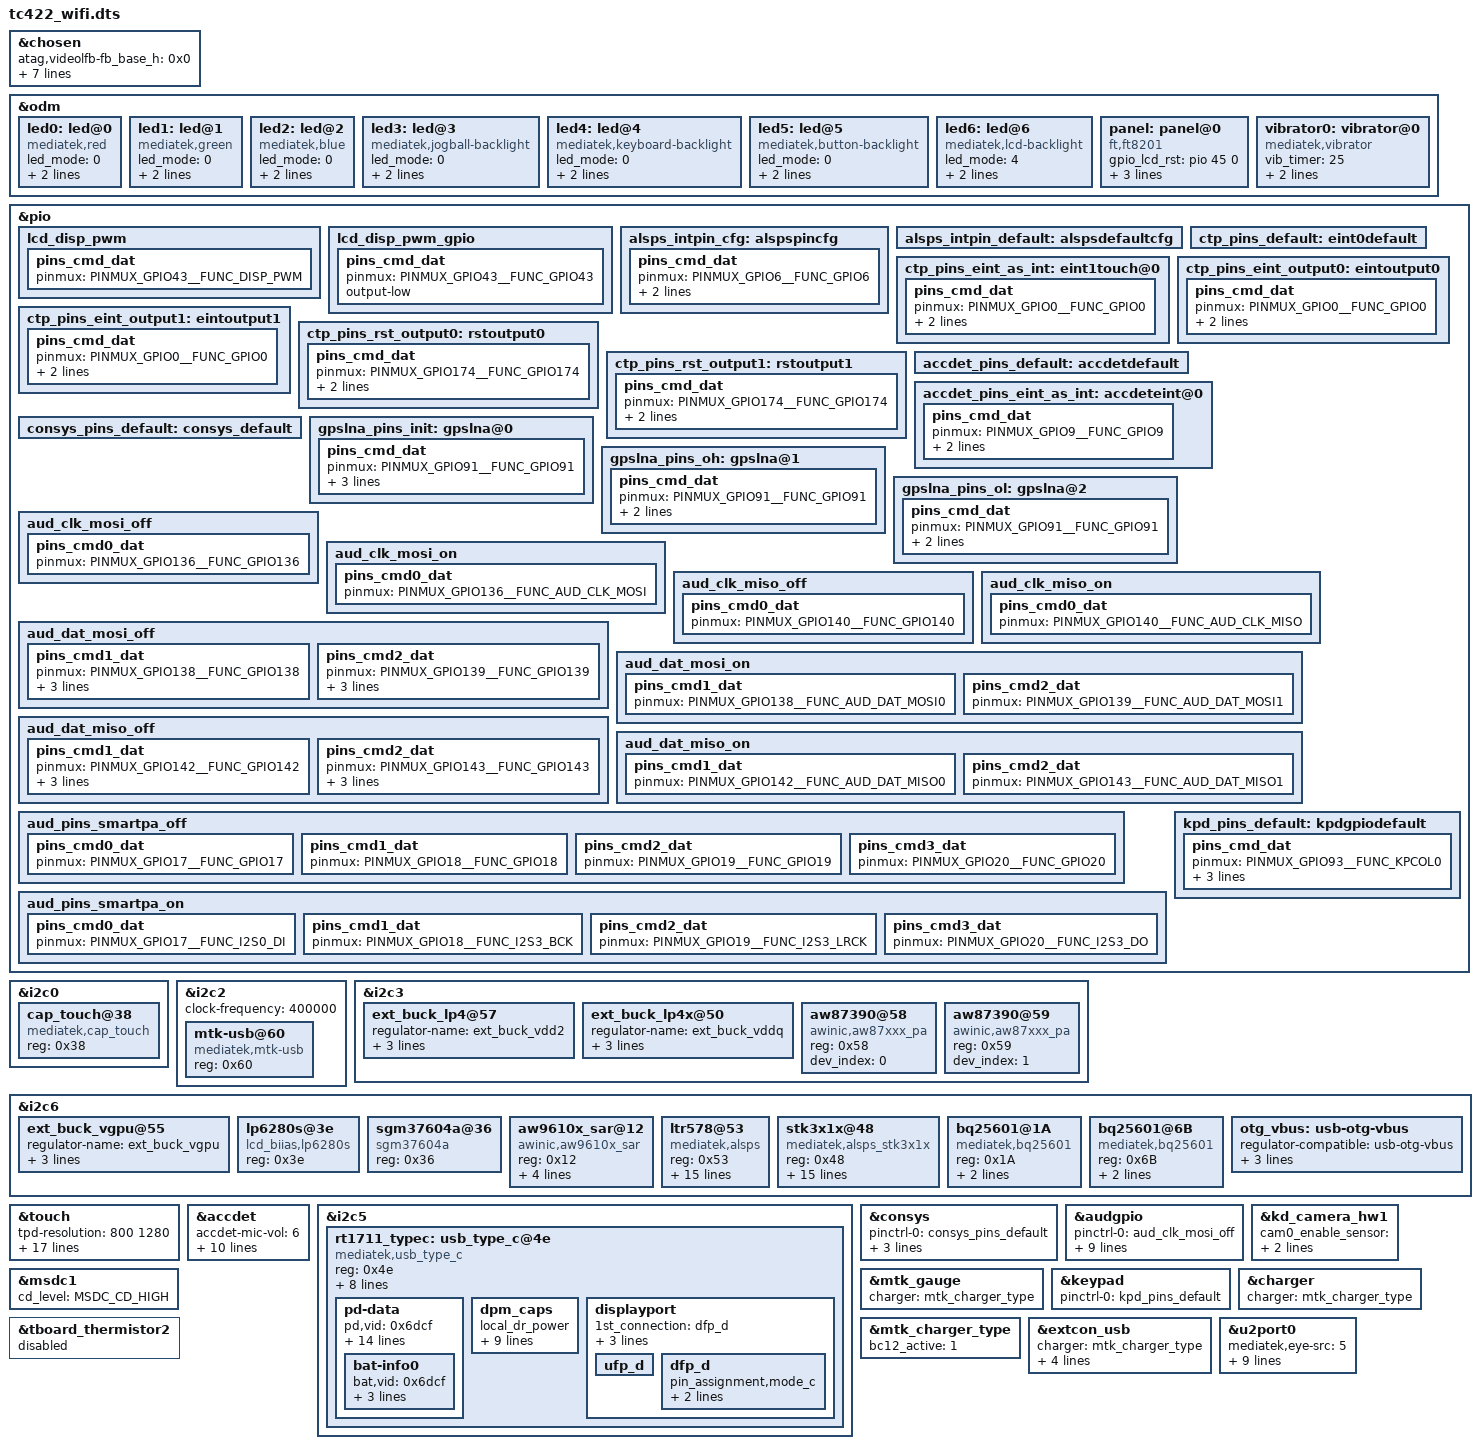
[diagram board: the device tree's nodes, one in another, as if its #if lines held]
// SPDX-License-Identifier: GPL-2.0+
/*
 * Copyright (c) 2019 MediaTek Inc.
 *
 */

#include <dt-bindings/interrupt-controller/arm-gic.h>
#include <dt-bindings/interrupt-controller/irq.h>
#include <dt-bindings/pinctrl/mt6761-pinfunc.h>
#include <dt-bindings/mmc/mt6761-msdc.h>
#include <dt-bindings/clock/mt6761-clk.h>

/dts-v1/;
/plugin/;

/* chosen */
&chosen {

	/* fpga may has no lk, we need to specify display info here */
	/* fb buffer is reserved using this dts by memory node above */
	atag,videolfb-fb_base_h = <0x0>;
	atag,videolfb-fb_base_l = <0x5e605000>;
	atag,videolfb-islcmfound = <1>;
	/* because no lk, so lcm is not inited */
	atag,videolfb-islcm_inited = <0>;
	atag,videolfb-fps= <6000>;
	atag,videolfb-vramSize= <0x017bb000>;
	atag,videolfb-lcmname= "nt35521_hd_dsi_vdo_truly_rt5081_drv";
};

&odm {
	led0:led@0 {
		compatible = "mediatek,red";
		led_mode = <0>;
		data = <1>;
		pwm_config = <0 0 0 0 0>;
	};
	led1:led@1 {
		compatible = "mediatek,green";
		led_mode = <0>;
		data = <1>;
		pwm_config = <0 0 0 0 0>;
	};
	led2:led@2 {
		compatible = "mediatek,blue";
		led_mode = <0>;
		data = <1>;
		pwm_config = <0 0 0 0 0>;
	};
	led3:led@3 {
		compatible = "mediatek,jogball-backlight";
		led_mode = <0>;
		data = <1>;
		pwm_config = <0 0 0 0 0>;
	};
	led4:led@4 {
		compatible = "mediatek,keyboard-backlight";
		led_mode = <0>;
		data = <1>;
		pwm_config = <0 0 0 0 0>;
	};
	led5:led@5 {
		compatible = "mediatek,button-backlight";
		led_mode = <0>;
		data = <1>;
		pwm_config = <0 0 0 0 0>;
	};
	led6:led@6 {
		compatible = "mediatek,lcd-backlight";
		led_mode = <4>;
		data = <1>;
		pwm_config = <0 3 0 0 0>;
	};
	panel: panel@0 {
		compatible = "ft,ft8201";
		gpio_lcd_rst = <&pio 45 0>;
		gpio_lcd_led_en = <&pio 153 0>;  //??????
		gpio_lcd_pwr_enp = <&pio 168 0>;//avdd
		gpio_lcd_pwr_enn = <&pio 173 0>;//avee
//		pinctrl-names = "disp_pwm", "disp_pwm_gpio";
//		pinctrl-0 = <&lcd_disp_pwm>;
//		pinctrl-1 = <&lcd_disp_pwm_gpio>;
	};
	vibrator0:vibrator@0 {
		compatible = "mediatek,vibrator";
		vib_timer = <25>;
		vib_limit = <9>;
		vib_vol= <9>;
	};
};

&pio {
	lcd_disp_pwm: lcd_disp_pwm {
		pins_cmd_dat {
			pinmux = <PINMUX_GPIO43__FUNC_DISP_PWM>;
		};
	};

	lcd_disp_pwm_gpio: lcd_disp_pwm_gpio {
		pins_cmd_dat {
			pinmux = <PINMUX_GPIO43__FUNC_GPIO43>;
			output-low;
		};
	};
};

&i2c0 {
	cap_touch@38 {
		compatible = "mediatek,cap_touch" ;
		reg = < 0x38 > ;
		status = "okay" ;
	};
};

&i2c2 {
	#address-cells = <1>;
	#size-cells = <0>;
	clock-frequency = <400000>;

	mtk-usb@60 {
		compatible = "mediatek,mtk-usb";
		reg = <0x60>;
		status = "okay";
	};
};

&i2c3 {
	ext_buck_lp4@57 {
		regulator-name ="ext_buck_vdd2";
		regulator-min-microvolt = <300000>;
		regulator-max-microvolt = <1300000>;
		vsel_pin = <0>;
	};

	ext_buck_lp4x@50 {
		regulator-name ="ext_buck_vddq";
		regulator-min-microvolt = <300000>;
		regulator-max-microvolt = <1300000>;
		vsel_pin = <1>;
	};

	aw87390@58 {
		compatible = "awinic,aw87xxx_pa";
		reg = <0x58>;
		//reset-gpio = <&pio 174 0>;
		dev_index = < 0 >;
		status = "okay";
	};

	aw87390@59 {
		compatible = "awinic,aw87xxx_pa";
		reg = <0x59>;
		//reset-gpio = <&pio 174 0>;
		dev_index = < 1 >;
		status = "okay";
	};

};

&i2c6 {
	ext_buck_vgpu@55 {
		regulator-name ="ext_buck_vgpu";
		regulator-min-microvolt = <300000>;
		regulator-max-microvolt = <1300000>;
		vsel_pin = <2>;
	};

	lp6280s@3e {
		compatible = "lcd_biias,lp6280s";
		reg = <0x3e>;
		status = "okay";
	};
	
	sgm37604a@36 {
		compatible = "sgm37604a";
		reg = <0x36>;
		status = "okay";
	};

	/*boe by linliangsong,add sensor,20220607,beigin*/
       aw9610x_sar@12 {
               compatible = "awinic,aw9610x_sar";
               reg = <0x12>;
               irq-gpio = <&pio 9 0x00>;
               aw9610x,using-firmware;
               //vcc0-supply = <&pm660l_l4>;
               channel_use_flag = <0x1f>;
               sar-num = < 0 >;
               status = "okay";
       };
      ltr578@53 {
               compatible = "mediatek,alsps";
               reg = <0x53>;
	       interrupt-parent = <&pio>;
	       interrupts = <6 IRQ_TYPE_LEVEL_LOW 6 0>;
	       debounce = <10 0>;
	       pinctrl-names = "pin_default", "pin_cfg";
	       pinctrl-0 = <&alsps_intpin_default>;
		pinctrl-1 = <&alsps_intpin_cfg>;
               status = "okay";
               i2c_num = <6>;
               i2c_addr = <0x53 0x0 0x0 0x00>;
               polling_mode_ps = <0>;
               polling_mode_als = <1>;
               power_id = <0xffff>;
               power_vol = <0>;
		als_level = <0 328 861 1377 3125 7721 7767 12621 23062 28430 33274 47116 57694 57694 65535>;
		als_value = <0 200 320 502 1004 2005 3058 5005 8008 10010 12000 16000 20000 20000 20000 20000>;
               //irq-gpio = <&pio 6 0x00>;               
      };
      /*boe by linliangsong,add sensor,20220607,end*/
      stk3x1x@48 {
               compatible = "mediatek,alsps_stk3x1x";
               reg = <0x48>;
               interrupt-parent = <&pio>;
               interrupts = <6 IRQ_TYPE_LEVEL_LOW 6 0>;
               debounce = <10 0>;
               pinctrl-names = "pin_default", "pin_cfg";
               pinctrl-0 = <&alsps_intpin_default>;
               pinctrl-1 = <&alsps_intpin_cfg>;
               status = "okay";
               i2c_num = <6>;
               i2c_addr = <0x48 0x0 0x0 0x00>;
               polling_mode_ps = <0>;
               polling_mode_als = <1>;
               power_id = <0xffff>;
               power_vol = <0>;
               als_level = <0 328 861 1377 3125 7721 7767 12621 23062 28430 33274 47116 57694 57694 65535>;
               als_value = <0 200 320 502 1004 2005 3058 5005 8008 10010 12000 16000 20000 20000 20000 20000>;
               //irq-gpio = <&pio 6 0x00>;
      };
	bq25601@1A {
		status = "okay";
		compatible = "mediatek,bq25601";
		reg = <0x1A>;
		charger_name = "primary_chg";
		alias_name = "sgm41513";
	};

	bq25601@6B {
		status = "okay";
		compatible = "mediatek,bq25601";
		reg = <0x6B>;
		charger_name = "primary_chg";
		alias_name = "sy6974";
	};

	otg_vbus: usb-otg-vbus {
		regulator-compatible = "usb-otg-vbus";
		regulator-name = "usb-otg-vbus";
		regulator-min-microvolt = <5000000>;
		regulator-max-microvolt = <5000000>;
	};
};
/*boe by linliangsong,add sensor,20220607,beigin*/
&pio {
	alsps_intpin_cfg: alspspincfg {

		pins_cmd_dat {
			pinmux = <PINMUX_GPIO6__FUNC_GPIO6>;
			slew-rate = <0>;
			bias-pull-up = <MTK_PUPD_SET_R1R0_01>;
		};
	};

	alsps_intpin_default: alspsdefaultcfg {

	};

};
/*boe by linliangsong,add sensor,20220607,end*/

/* TOUCH start */
&touch {
	tpd-resolution = <800 1280>;
	use-tpd-button = <0>;
	tpd-key-num = <3>;
	tpd-key-local= <139 172 158 0>;
	tpd-key-dim-local = <90 883 100 40 230
				 883 100 40 370 883 100 40 0 0 0 0>;
	tpd-max-touch-num = <10>;
	tpd-filter-enable = <0>;
	tpd-filter-pixel-density = <106>;
	tpd-filter-custom-prameters = <0 0 0 0 0 0 0 0 0 0 0 0>;
	tpd-filter-custom-speed = <0 0 0>;
	pinctrl-names = "default", "state_eint_as_int", "state_eint_output0",
		"state_eint_output1", "state_rst_output0", "state_rst_output1";
	pinctrl-0 = <&ctp_pins_default>;
	pinctrl-1 = <&ctp_pins_eint_as_int>;
	pinctrl-2 = <&ctp_pins_eint_output0>;
	pinctrl-3 = <&ctp_pins_eint_output1>;
	pinctrl-4 = <&ctp_pins_rst_output0>;
	pinctrl-5 = <&ctp_pins_rst_output1>;
	status = "okay";
};
&pio {
	ctp_pins_default: eint0default {
	};
	ctp_pins_eint_as_int: eint1touch@0 {
		pins_cmd_dat {
			pinmux = <PINMUX_GPIO0__FUNC_GPIO0>;
			slew-rate = <0>;
			bias-disable;
		};
	};
	ctp_pins_eint_output0: eintoutput0 {
		pins_cmd_dat {
			pinmux = <PINMUX_GPIO0__FUNC_GPIO0>;
			slew-rate = <1>;
			output-low;
		};
	};
	ctp_pins_eint_output1: eintoutput1 {
		pins_cmd_dat {
			pinmux = <PINMUX_GPIO0__FUNC_GPIO0>;
			slew-rate = <1>;
			output-high;
		};
	};
	ctp_pins_rst_output0: rstoutput0 {
		pins_cmd_dat {
			pinmux = <PINMUX_GPIO174__FUNC_GPIO174>;
			slew-rate = <1>;
			output-low;
		};
	};
	ctp_pins_rst_output1: rstoutput1 {
		pins_cmd_dat {
			pinmux = <PINMUX_GPIO174__FUNC_GPIO174>;
			slew-rate = <1>;
			output-high;
		};
	};
};
/* TOUCH end */
&accdet {
	accdet-mic-vol = <6>;
	headset-mode-setting = <0x500 0x500 1 0x1f0 0x800 0x800 0x20 0x44>;
	accdet-plugout-debounce = <1>;
	accdet-mic-mode = <1>;
	headset-eint-level-pol = <8>;
	headset-three-key-threshold = <0 80 220 400>;
	headset-three-key-threshold-CDD = <0 121 192 600>;
	headset-four-key-threshold = <0 58 121 192 400>;
	pinctrl-names = "default", "state_eint_as_int";
	pinctrl-0 = <&accdet_pins_default>;
	pinctrl-1 = <&accdet_pins_eint_as_int>;
	status = "okay";
};
&pio {
	accdet_pins_default: accdetdefault {
	};
	accdet_pins_eint_as_int: accdeteint@0 {
		pins_cmd_dat {
			pinmux = <PINMUX_GPIO9__FUNC_GPIO9>;
			slew-rate = <0>;
			bias-disable;
		};
	};
};

&i2c5 {
    status = "okay";

    rt1711_typec: usb_type_c@4e {
        compatible = "mediatek,usb_type_c";
        reg = <0x4e>;

        rt-tcpc,name = "type_c_port0"; /* tcpc_device's name */
        rt-tcpc,role_def = <5>; /* 0: Unknown, 1: SNK, 2: SRC */
                    /* 3: DRP, 4: Try.SRC, 5: Try.SNK */
        rt-tcpc,rp_level = <0>; /* 0: Default, 1: 1.5, 2: 3.0 */
        rt-tcpc,vconn_supply  = <1>;  /* 0: Never, 1: Always, */
                          /* 2: EMarkOnly, 3: StartOnly */
#if (CONFIG_MTK_GAUGE_VERSION == 30)
        rt-tcpc,notifier_supply_num = <3>;
#else
        rt-tcpc,notifier_supply_num = <2>;
#endif
        rt1711pd,intr_gpio = <&pio 5 0x0>;
        rt1711pd,intr_gpio_num = <5>;

		charger = <&charger>;

        pd-data {
            pd,vid = <0x6dcf>;
            pd,pid = <0x1711>;
            pd,source-cap-ext = <0x17116dcf 0x00000000 0x00000000
                         0x00000000 0x00000000 0x02000000>;
            pd,mfrs = "RichtekTCPC";

            /*
             *  VSAFE5V = 0, MAX_POWER = 1, CUSTOM = 2,
             *  MAX_POWER_LV = 0x21, MAX_POWER_LVIC = 0x31
             *  MAX_POWER_HV = 0x41, MAX_POWER_HVIC = 0x51
             */
            pd,charging_policy= <0x31>;

            /*
             * Fixed 5V, 500 mA <0x00019032>
             * Fixed 5V, 1A <0x00019064>
             * Fixed 5V, 2A <0x000190c8>
             * Fixed 5V, 3A <0x0001912c>
             * Fixed 9V, 500 mA <0x0002d032>
             * Fixed 9V, 1A <0x0002d064>
             * Fixed 9V, 2A <0x0002d0c8>
             * Fixed 9V, 3A <0x0002d12c>
             * Variable 5-9V, 1A <0x8642d064>
             * Variable 5-9V, 2A <0x8642d0c8>
             * Variable 5-9V, 3A <0x8642d12c>
             * PPS 3V~5.9V, 3A <0xC0761E3C>
             */
            pd,source-pdo-size = <1>;
            pd,source-pdo-data = <0x00019032>;
            pd,sink-pdo-size = <1>;
            pd,sink-pdo-data = <0x000190c8>;

            /*
             * No DP, host + device
             *  pd,id-vdo-size = <6>;
             *  pd,id-vdo-data = <0xd1406dcf 0x0 0x17110000
                          0x41800000 0x0 0x21800000>;
             * With DP
             *  pd,id-vdo-size = <6>;
             *  pd,id-vdo-data = <0xd5406dcf 0x0 0x17110000
                          0x41800000 0x0 0x21800000>;
             */

            pd,id-vdo-size = <6>;
            pd,id-vdo-data = <0xd1406dcf 0x0 0x17110000
                      0x41800000 0x0 0x21800000>;

            bat,nr = <1>;
            pd,country_nr = <0>;

            bat-info0 {
                bat,vid = <0x6dcf>;
                bat,pid = <0x1711>;
                bat,mfrs = "bat1";
                bat,design_cap = <5000>;
            };

            //bat-info1 {
            //  bat,vid = <0x8abc>;
            //  bat,pid = <0x5234>;
            //  bat,mfrs = "bat2";
            //  bat,design_cap = <4000>;
            //};

            //country0 {
            //  pd,country_code = <0x5457>;
            //  pd,country_len = <2>; /* max len = 26 */
            //  pd,country_data = <0xff 0xff>;
            //};

            //country1 {
            //  pd,country_code = <0x5553>;
            //  pd,country_len = <3>; /* max len = 26 */
            //  pd,country_data = <0xf1 0xf2 0xf3>;
            //};
        };
        dpm_caps {
            local_dr_power;
            local_dr_data;
            //local_ext_power;
            local_usb_comm;
            //local_usb_suspend;
            //local_high_cap;
            //local_give_back;
            local_no_suspend;
            local_vconn_supply;

            //attemp_discover_cable_dfp;
            attemp_enter_dp_mode;
           attemp_discover_cable;
            attemp_discover_id;

            /* 0: disable, 1: prefer_snk, 2: prefer_src */
            pr_check = <0>;
            //pr_reject_as_source;
            //pr_reject_as_sink;
            //pr_check_gp_source;
            //pr_check_gp_sink;

            /* 0: disable, 1: prefer_ufp, 2: prefer_dfp */
            dr_check = <0>;
            //dr_reject_as_dfp;
            //dr_reject_as_ufp;
        };
        displayport {
            /* connection type = "both", "ufp_d", "dfp_d" */
            1st_connection = "dfp_d";
            2nd_connection = "dfp_d";
            signal,dp_v13;
            //signal,dp_gen2;
            //usbr20_not_used;
            typec,receptacle;
            ufp_d {
                //pin_assignment,mode_a;
                //pin_assignment,mode_b;
                //pin_assignment,mode_c;
                //pin_assignment,mode_d;
                //pin_assignment,mode_e;
            };
            dfp_d {
                //pin_assignment,mode_a;
                //pin_assignment,mode_b;
                pin_assignment,mode_c;
                pin_assignment,mode_d;
                pin_assignment,mode_e;
                //pin_assignment,mode_f;
            };
        };
    };

};

/* CONSYS GPIO standardization */
&pio {
	consys_pins_default: consys_default {
	};
	gpslna_pins_init: gpslna@0 {
		pins_cmd_dat {
			pinmux = <PINMUX_GPIO91__FUNC_GPIO91>;
			slew-rate = <0>;
			bias-disable;
			output-low;
		};
	};
	gpslna_pins_oh: gpslna@1 {
		pins_cmd_dat {
			pinmux = <PINMUX_GPIO91__FUNC_GPIO91>;
			slew-rate = <1>;
			output-high;
		};
	};
	gpslna_pins_ol: gpslna@2 {
		pins_cmd_dat {
			pinmux = <PINMUX_GPIO91__FUNC_GPIO91>;
			slew-rate = <1>;
			output-low;
		};
	};
};
&consys {
	pinctrl-names = "default", "gps_lna_state_init",
		"gps_lna_state_oh", "gps_lna_state_ol";
	pinctrl-0 = <&consys_pins_default>;
	pinctrl-1 = <&gpslna_pins_init>;
	pinctrl-2 = <&gpslna_pins_oh>;
	pinctrl-3 = <&gpslna_pins_ol>;
	status = "okay";
};
/* CONSYS end */

/* AUDIO GPIO standardization */
&audgpio {
	pinctrl-names = "aud_clk_mosi_off",
			"aud_clk_mosi_on",
			"aud_clk_miso_off",
			"aud_clk_miso_on",
			"aud_dat_mosi_off",
			"aud_dat_mosi_on",
			"aud_dat_miso_off",
			"aud_dat_miso_on",
			"aud_smartpa_off",
			"aud_smartpa_on";
	pinctrl-0 = <&aud_clk_mosi_off>;
	pinctrl-1 = <&aud_clk_mosi_on>;
	pinctrl-2 = <&aud_clk_miso_off>;
	pinctrl-3 = <&aud_clk_miso_on>;
	pinctrl-4 = <&aud_dat_mosi_off>;
	pinctrl-5 = <&aud_dat_mosi_on>;
	pinctrl-6 = <&aud_dat_miso_off>;
	pinctrl-7 = <&aud_dat_miso_on>;
	pinctrl-8 = <&aud_pins_smartpa_off>;
	pinctrl-9 = <&aud_pins_smartpa_on>;
	status = "okay";
};

&pio {
	aud_clk_mosi_off: aud_clk_mosi_off {
		pins_cmd0_dat {
			pinmux = <PINMUX_GPIO136__FUNC_GPIO136>;
		};
	};

	aud_clk_mosi_on: aud_clk_mosi_on {
		pins_cmd0_dat {
			pinmux = <PINMUX_GPIO136__FUNC_AUD_CLK_MOSI>;
		};
	};

	aud_clk_miso_off: aud_clk_miso_off {
		pins_cmd0_dat {
			pinmux = <PINMUX_GPIO140__FUNC_GPIO140>;
		};
	};

	aud_clk_miso_on: aud_clk_miso_on {
		pins_cmd0_dat {
			pinmux = <PINMUX_GPIO140__FUNC_AUD_CLK_MISO>;
		};
	};

	aud_dat_mosi_off: aud_dat_mosi_off {
		pins_cmd1_dat {
			pinmux = <PINMUX_GPIO138__FUNC_GPIO138>;
			input-enable;
			slew-rate = <0>;
			bias-disable;
		};
		pins_cmd2_dat {
			pinmux = <PINMUX_GPIO139__FUNC_GPIO139>;
			input-enable;
			slew-rate = <0>;
			bias-disable;
		};
	};

	aud_dat_mosi_on: aud_dat_mosi_on {
		pins_cmd1_dat {
			pinmux = <PINMUX_GPIO138__FUNC_AUD_DAT_MOSI0>;
		};
		pins_cmd2_dat {
			pinmux = <PINMUX_GPIO139__FUNC_AUD_DAT_MOSI1>;
		};
	};

	aud_dat_miso_off: aud_dat_miso_off {
		pins_cmd1_dat {
			pinmux = <PINMUX_GPIO142__FUNC_GPIO142>;
			input-enable;
			slew-rate = <0>;
			bias-disable;
		};
		pins_cmd2_dat {
			pinmux = <PINMUX_GPIO143__FUNC_GPIO143>;
			input-enable;
			slew-rate = <0>;
			bias-disable;
		};
	};

	aud_dat_miso_on: aud_dat_miso_on {
		pins_cmd1_dat {
			pinmux = <PINMUX_GPIO142__FUNC_AUD_DAT_MISO0>;
		};
		pins_cmd2_dat {
			pinmux = <PINMUX_GPIO143__FUNC_AUD_DAT_MISO1>;
		};
	};

	aud_pins_smartpa_off: aud_pins_smartpa_off {
		pins_cmd0_dat {
			pinmux = <PINMUX_GPIO17__FUNC_GPIO17>;
		};
		pins_cmd1_dat {
			pinmux = <PINMUX_GPIO18__FUNC_GPIO18>;
		};
		pins_cmd2_dat {
			pinmux = <PINMUX_GPIO19__FUNC_GPIO19>;
		};
		pins_cmd3_dat {
			pinmux = <PINMUX_GPIO20__FUNC_GPIO20>;
		};
	};

	aud_pins_smartpa_on: aud_pins_smartpa_on {
		pins_cmd0_dat {
			pinmux = <PINMUX_GPIO17__FUNC_I2S0_DI>;
		};
		pins_cmd1_dat {
			pinmux = <PINMUX_GPIO18__FUNC_I2S3_BCK>;
		};
		pins_cmd2_dat {
			pinmux = <PINMUX_GPIO19__FUNC_I2S3_LRCK>;
		};
		pins_cmd3_dat {
			pinmux = <PINMUX_GPIO20__FUNC_I2S3_DO>;
		};
	};
};
/* AUDIO end */

/* CAMERA specify sensor */

&kd_camera_hw1 {
	cam0_enable_sensor = "gc5035_mipi_raw hi556_mipi_raw";
	cam1_enable_sensor = "gc2375h_mipi_raw";
};
/* CAMERA specify sensor end */

#include <tc422_wifi/cust.dtsi>
#include "cust_mt8766_camera.dtsi"

&msdc1 {
	cd_level = /bits/ 8 <MSDC_CD_HIGH>;
};

&mtk_gauge {
	charger = <&mtk_charger_type>;
};

&keypad {
	pinctrl-names = "default";
	pinctrl-0 = <&kpd_pins_default>;
};

&pio {
	kpd_pins_default: kpdgpiodefault {
		pins_cmd_dat {
			pinmux = <PINMUX_GPIO93__FUNC_KPCOL0>;
			bias-pull-up = <MTK_PUPD_SET_R1R0_10>;
			output-low;
			input-schmitt-enable;
		};
	};
};

&charger {
	charger = <&mtk_charger_type>;
};

&tboard_thermistor2 {
       status = "disabled";
};

&mtk_charger_type {
	bc12_active = <1>;
};

&extcon_usb {
	charger = <&mtk_charger_type>;
	vbus-supply = <&otg_vbus>;
	vbus-current;
	vbus-voltage;
	id-gpios = <&pio 41 0x0>;
};

&u2port0 {
	mediatek,eye-src = <5>;
	mediatek,eye-vrt = <4>;
	mediatek,eye-term = <4>;
	mediatek,eye-rev6 = <1>;
	mediatek,eye-disc = <15>;
	mediatek,host-eye-src = <5>;
	mediatek,host-eye-vrt = <4>;
	mediatek,host-eye-term = <4>;
	mediatek,host-eye-rev6 = <1>;
	mediatek,host-eye-disc = <15>;
};
/*End of this file, DO NOT ADD ANYTHING HERE*/
